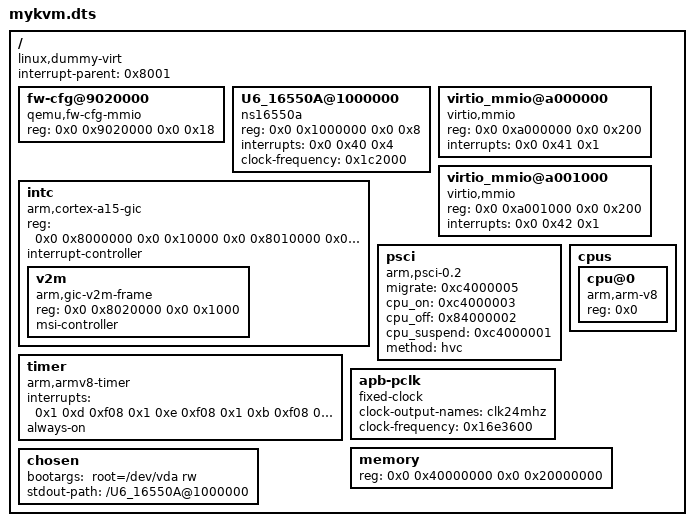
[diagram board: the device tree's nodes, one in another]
/dts-v1/;

/ {
	interrupt-parent = <0x8001>;
	#size-cells = <0x2>;
	#address-cells = <0x2>;
	compatible = "linux,dummy-virt";

	fw-cfg@9020000 {
		reg = <0x0 0x9020000 0x0 0x18>;
		compatible = "qemu,fw-cfg-mmio";
	};

	U6_16550A@1000000 {
		compatible = "ns16550a";
		reg = <0x0 0x1000000 0x0 0x8>;
		interrupts = <0x0 0x40 0x4>;
		clock-frequency = <0x1c2000>;
	};

	//blk
	virtio_mmio@a000000 {
		compatible = "virtio,mmio";
		reg = <0x0 0xa000000 0x0 0x200>;
		interrupts = <0x0 0x41 0x1>;
	};

	//net
	virtio_mmio@a001000 {
		compatible = "virtio,mmio";
		reg = <0x0 0xa001000 0x0 0x200>;
		interrupts = <0x0 0x42 0x1>;
	};

	intc {
		phandle = <0x8001>;
		reg = <0x0 0x8000000 0x0 0x10000 0x0 0x8010000 0x0 0x10000>;
		compatible = "arm,cortex-a15-gic";
		ranges;
		#size-cells = <0x2>;
		#address-cells = <0x2>;
		interrupt-controller;
		#interrupt-cells = <0x3>;

		v2m {
			phandle = <0x8002>;
			reg = <0x0 0x8020000 0x0 0x1000>;
			msi-controller;
			compatible = "arm,gic-v2m-frame";
		};
	};

	psci {
		migrate = <0xc4000005>;
		cpu_on = <0xc4000003>;
		cpu_off = <0x84000002>;
		cpu_suspend = <0xc4000001>;
		method = "hvc";
		compatible = "arm,psci-0.2", "arm,psci";
	};

	cpus {
		#size-cells = <0x0>;
		#address-cells = <0x1>;

		cpu@0 {
			reg = <0x0>;
			compatible = "arm,arm-v8";
			device_type = "cpu";
		};
	};

	timer {
		compatible = "arm,armv8-timer", "arm,armv7-timer";
		interrupts = <0x1 0xd 0xf08 0x1 0xe 0xf08 0x1 0xb 0xf08 0x1 0xa 0xf08>;
		always-on;
	};

	apb-pclk {
		phandle = <0x8000>;
		clock-output-names = "clk24mhz";
		clock-frequency = <0x16e3600>;
		#clock-cells = <0x0>;
		compatible = "fixed-clock";
	};

	memory {
		reg = <0x0 0x40000000 0x0 0x20000000>;
		device_type = "memory";
	};

	chosen {
		bootargs = " root=/dev/vda rw ";
		//linux,initrd-end = <0x4844cad3>;
		//linux,initrd-start = <0x48000000>;
		stdout-path = "/U6_16550A@1000000";
	};
};
